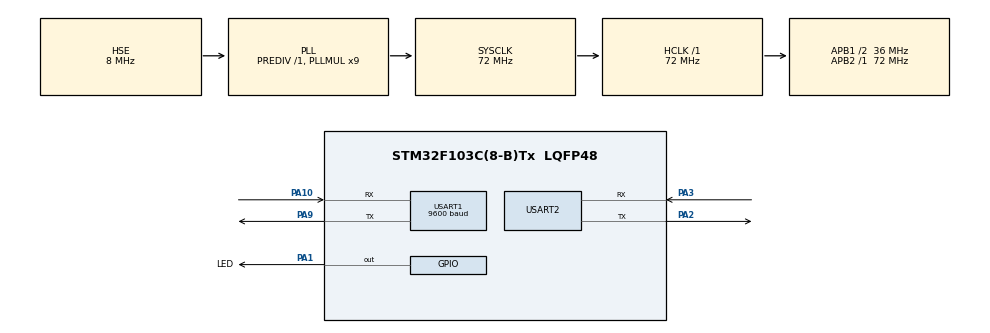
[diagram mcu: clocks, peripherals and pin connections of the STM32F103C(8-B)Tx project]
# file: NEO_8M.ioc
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Mcu.Family=STM32F1
Mcu.Name=STM32F103C(8-B)Tx
Mcu.Package=LQFP48
NVIC.PriorityGroup=NVIC_PRIORITYGROUP_4
NVIC.USART1_IRQn=true\:0\:0\:false\:false\:true\:true\:true\:true
PA1.GPIO_Label=LED
PA1.Signal=GPIO_Output
PA10.Mode=Asynchronous
PA10.Signal=USART1_RX
PA13.Mode=Serial_Wire
PA13.Signal=SYS_JTMS-SWDIO
PA14.Mode=Serial_Wire
PA14.Signal=SYS_JTCK-SWCLK
PA2.Mode=Asynchronous
PA2.Signal=USART2_TX
PA3.Mode=Asynchronous
PA3.Signal=USART2_RX
PA9.Mode=Asynchronous
PA9.Signal=USART1_TX
PD0-OSC_IN.Mode=HSE-External-Oscillator
PD0-OSC_IN.Signal=RCC_OSC_IN
PD1-OSC_OUT.Mode=HSE-External-Oscillator
PD1-OSC_OUT.Signal=RCC_OSC_OUT
ProjectManager.HeapSize=0x200
ProjectManager.StackSize=0x400
ProjectManager.TargetToolchain=STM32CubeIDE
RCC.AHBFreq_Value=72000000
RCC.APB1CLKDivider=RCC_HCLK_DIV2
RCC.APB1Freq_Value=36000000
RCC.APB1TimFreq_Value=72000000
RCC.APB2Freq_Value=72000000
RCC.APB2TimFreq_Value=72000000
RCC.HCLKFreq_Value=72000000
RCC.HSICalibrationValue=8
RCC.PLLMUL=RCC_PLL_MUL9
RCC.PLLSourceVirtual=RCC_PLLSOURCE_HSE
RCC.SYSCLKFreq_VALUE=72000000
RCC.SYSCLKSource=RCC_SYSCLKSOURCE_PLLCLK
RCC.USBFreq_Value=72000000
USART1.BaudRate=9600
USART1.VirtualMode=VM_ASYNC
USART2.VirtualMode=VM_ASYNC
board=custom

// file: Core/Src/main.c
/* USER CODE BEGIN Header */
/**
  ******************************************************************************
  * @file           : main.c
  * @brief          : Main program body
  ******************************************************************************
  * @attention
  *
  * Copyright (c) 2023 STMicroelectronics.
  * All rights reserved.
  *
  * This software is licensed under terms that can be found in the LICENSE file
  * in the root directory of this software component.
  * If no LICENSE file comes with this software, it is provided AS-IS.
  *
  ******************************************************************************
  */
/* USER CODE END Header */
#include "main.h"

/* USER CODE BEGIN Includes */
#include "M8N.h"
/* USER CODE END Includes */

/* USER CODE BEGIN PTD */
#define PUTCHAR_PROTOTYPE int __io_putchar(int ch)
/* USER CODE END PTD */

UART_HandleTypeDef huart2;

/* USER CODE BEGIN PV */
extern uint8_t m8n_rx_buf[36];
extern uint8_t m8n_rx_cplt_flag;
/* USER CODE END PV */

void SystemClock_Config(void);
static void MX_GPIO_Init(void);
static void MX_USART1_UART_Init(void);
static void MX_USART2_UART_Init(void);

int main(void)
{

  /* MCU Configuration--------------------------------------------------------*/

  /* Reset of all peripherals, Initializes the Flash interface and the Systick. */
  HAL_Init();

  /* Configure the system clock */
  SystemClock_Config();

  /* Initialize all configured peripherals */
  MX_GPIO_Init();
  MX_USART1_UART_Init();
  MX_USART2_UART_Init();
  /* USER CODE BEGIN 2 */
  LL_USART_EnableIT_RXNE(USART1);
  /* USER CODE END 2 */

  /* Infinite loop */
  while (1)
  {

    /* USER CODE BEGIN 3 */
	  if(m8n_rx_cplt_flag == 1)
	  {
		  m8n_rx_cplt_flag = 0;

		  if(M8N_UBX_CHKSUM_Check(&m8n_rx_buf[0], 36) == 1)
		  {
			  HAL_GPIO_TogglePin(LED_GPIO_Port, LED_Pin);
			  M8N_UBX_NAV_POSLLH_Parsing(&m8n_rx_buf[0], &posllh);
			  printf("LAT: %ld\tLON: %ld\tHeight: %ld\n", posllh.lat, posllh.lon);
		  }
	  }
  }
  /* USER CODE END 3 */
}

void SystemClock_Config(void)
{
  RCC_OscInitTypeDef RCC_OscInitStruct = {0};
  RCC_ClkInitTypeDef RCC_ClkInitStruct = {0};

  /** Initializes the RCC Oscillators according to the specified parameters
  * in the RCC_OscInitTypeDef structure.
  */
  RCC_OscInitStruct.OscillatorType = RCC_OSCILLATORTYPE_HSE;
  RCC_OscInitStruct.HSEState = RCC_HSE_ON;
  RCC_OscInitStruct.HSEPredivValue = RCC_HSE_PREDIV_DIV1;
  RCC_OscInitStruct.HSIState = RCC_HSI_ON;
  RCC_OscInitStruct.PLL.PLLState = RCC_PLL_ON;
  RCC_OscInitStruct.PLL.PLLSource = RCC_PLLSOURCE_HSE;
  RCC_OscInitStruct.PLL.PLLMUL = RCC_PLL_MUL9;
  if (HAL_RCC_OscConfig(&RCC_OscInitStruct) != HAL_OK)
  {
    Error_Handler();
  }

  /** Initializes the CPU, AHB and APB buses clocks
  */
  RCC_ClkInitStruct.ClockType = RCC_CLOCKTYPE_HCLK|RCC_CLOCKTYPE_SYSCLK
                              |RCC_CLOCKTYPE_PCLK1|RCC_CLOCKTYPE_PCLK2;
  RCC_ClkInitStruct.SYSCLKSource = RCC_SYSCLKSOURCE_PLLCLK;
  RCC_ClkInitStruct.AHBCLKDivider = RCC_SYSCLK_DIV1;
  RCC_ClkInitStruct.APB1CLKDivider = RCC_HCLK_DIV2;
  RCC_ClkInitStruct.APB2CLKDivider = RCC_HCLK_DIV1;

  if (HAL_RCC_ClockConfig(&RCC_ClkInitStruct, FLASH_LATENCY_2) != HAL_OK)
  {
    Error_Handler();
  }
}

static void MX_USART1_UART_Init(void)
{

  LL_USART_InitTypeDef USART_InitStruct = {0};

  LL_GPIO_InitTypeDef GPIO_InitStruct = {0};

  /* Peripheral clock enable */
  LL_APB2_GRP1_EnableClock(LL_APB2_GRP1_PERIPH_USART1);

  LL_APB2_GRP1_EnableClock(LL_APB2_GRP1_PERIPH_GPIOA);
  /**USART1 GPIO Configuration
  PA9   ------> USART1_TX
  PA10   ------> USART1_RX
  */
  GPIO_InitStruct.Pin = LL_GPIO_PIN_9;
  GPIO_InitStruct.Mode = LL_GPIO_MODE_ALTERNATE;
  GPIO_InitStruct.Speed = LL_GPIO_SPEED_FREQ_HIGH;
  GPIO_InitStruct.OutputType = LL_GPIO_OUTPUT_PUSHPULL;
  LL_GPIO_Init(GPIOA, &GPIO_InitStruct);

  GPIO_InitStruct.Pin = LL_GPIO_PIN_10;
  GPIO_InitStruct.Mode = LL_GPIO_MODE_FLOATING;
  LL_GPIO_Init(GPIOA, &GPIO_InitStruct);

  /* USART1 interrupt Init */
  NVIC_SetPriority(USART1_IRQn, NVIC_EncodePriority(NVIC_GetPriorityGrouping(),0, 0));
  NVIC_EnableIRQ(USART1_IRQn);

  USART_InitStruct.BaudRate = 9600;
  USART_InitStruct.DataWidth = LL_USART_DATAWIDTH_8B;
  USART_InitStruct.StopBits = LL_USART_STOPBITS_1;
  USART_InitStruct.Parity = LL_USART_PARITY_NONE;
  USART_InitStruct.TransferDirection = LL_USART_DIRECTION_TX_RX;
  USART_InitStruct.HardwareFlowControl = LL_USART_HWCONTROL_NONE;
  USART_InitStruct.OverSampling = LL_USART_OVERSAMPLING_16;
  LL_USART_Init(USART1, &USART_InitStruct);
  LL_USART_ConfigAsyncMode(USART1);
  LL_USART_Enable(USART1);

}

static void MX_USART2_UART_Init(void)
{

  huart2.Instance = USART2;
  huart2.Init.BaudRate = 115200;
  huart2.Init.WordLength = UART_WORDLENGTH_8B;
  huart2.Init.StopBits = UART_STOPBITS_1;
  huart2.Init.Parity = UART_PARITY_NONE;
  huart2.Init.Mode = UART_MODE_TX_RX;
  huart2.Init.HwFlowCtl = UART_HWCONTROL_NONE;
  huart2.Init.OverSampling = UART_OVERSAMPLING_16;
  if (HAL_UART_Init(&huart2) != HAL_OK)
  {
    Error_Handler();
  }

}

static void MX_GPIO_Init(void)
{
  GPIO_InitTypeDef GPIO_InitStruct = {0};

  /* GPIO Ports Clock Enable */
  __HAL_RCC_GPIOD_CLK_ENABLE();
  __HAL_RCC_GPIOA_CLK_ENABLE();

  /*Configure GPIO pin Output Level */
  HAL_GPIO_WritePin(LED_GPIO_Port, LED_Pin, GPIO_PIN_RESET);

  /*Configure GPIO pin : LED_Pin */
  GPIO_InitStruct.Pin = LED_Pin;
  GPIO_InitStruct.Mode = GPIO_MODE_OUTPUT_PP;
  GPIO_InitStruct.Pull = GPIO_NOPULL;
  GPIO_InitStruct.Speed = GPIO_SPEED_FREQ_LOW;
  HAL_GPIO_Init(LED_GPIO_Port, &GPIO_InitStruct);

}

/* USER CODE BEGIN 4 */
PUTCHAR_PROTOTYPE
{
  /* Place your implementation of fputc here */
  /* e.g. write a character to the USART1 and Loop until the end of transmission */
  HAL_UART_Transmit(&huart2, (uint8_t *)&ch, 1, 0xFFFF);

  return ch;
}

/* USER CODE END 4 */

void Error_Handler(void)
{
  __disable_irq();
  while (1)
  {
  }
}
